# f2838x_cm_ethernetss_regs register map
Vendor: Texas Instruments
Peripheral module from a debugger description file (folder C2000).
Address unit: 16 bits
Registers are 32-bit, read-write, no defined reset value unless marked. A register's access mark holds for its fields unless they carry their own. Offsets are as the file gives them; lines under a group give offsets from that group; [hi:lo] are bit positions; {n}, {i} and the like mark numbered series; 'fields as' and 'values as' point back to an identical list; <NAME> marks a mode.

## ETHERNETSS_REGS — ETHERNETSS Registers
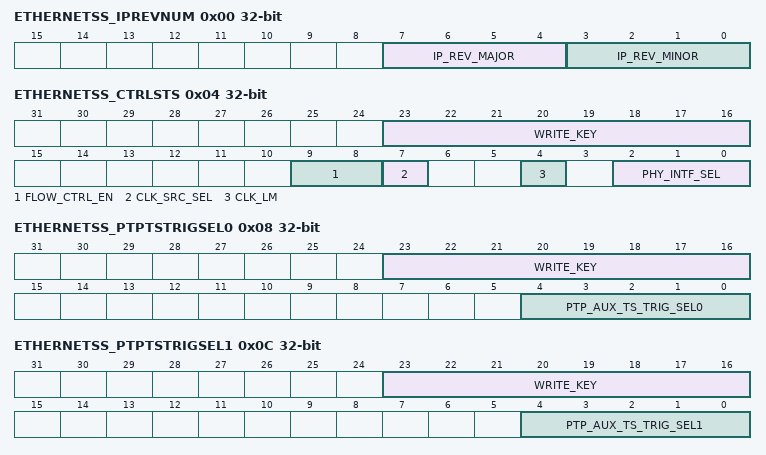
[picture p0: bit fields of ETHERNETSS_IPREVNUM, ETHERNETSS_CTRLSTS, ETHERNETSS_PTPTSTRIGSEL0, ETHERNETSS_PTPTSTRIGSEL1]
0x00 ETHERNETSS_IPREVNUM ro — IP Revision Number
  [7:4] IP_REV_MAJOR — Major IP Revision Number
  [3:0] IP_REV_MINOR — Minor IP Revision Number
0x04 ETHERNETSS_CTRLSTS access per field — Control Register
  [23:16] WRITE_KEY rw — Key to enable writing lock
  [9:8] FLOW_CTRL_EN rw — Back-pressure enable per receive queue.
  [7] CLK_SRC_SEL rw — Internal Clock Selection
  [4] CLK_LM ro — MII Loop-back mode clock select
  [2:0] PHY_INTF_SEL rw — PHY Type Selection
0x08 ETHERNETSS_PTPTSTRIGSEL0 — PTP Trigger-0 select
  [23:16] WRITE_KEY — Key to enable writing lock
  [4:0] PTP_AUX_TS_TRIG_SEL0 — Trigger select for Auxillary TS capture - 0
0x0C ETHERNETSS_PTPTSTRIGSEL1 — PTP Trigger-1 select
  [23:16] WRITE_KEY — Key to enable writing lock
  [4:0] PTP_AUX_TS_TRIG_SEL1 — Trigger select for Auxillary TS capture - 1
0x10 ETHERNETSS_PTPTSSWTRIG0 — PTP SW Trigger-0
  [0] PTP_AUX_TS_SW_TRIG0 — SW trigger for AUX TS capture for trigger-0
0x14 ETHERNETSS_PTPTSSWTRIG1 — PTP SW Trigger-1
  [0] PTP_AUX_TS_SW_TRIG1 — SW trigger for AUX TS capture for trigger-1
0x18 ETHERNETSS_PTPPPSR0 ro — PTP PPS-0 Read
  [0] PTP_PPS_R0 — Registered value of Pulse Per Second-0
0x1C ETHERNETSS_PTPPPSR1 ro — PTP PPS-1 Read
  [0] PTP_PPS_R1 — Registered value of Pulse Per Second-1
0x20 ETHERNETSS_PTP_TSRL ro — PTP timestamp read lower 32 bits
  [31:0] TSR_L — Time-stamp o/p from the EQOS Low
0x24 ETHERNETSS_PTP_TSRH ro — PTP timestamp read upper 32 bits
  [31:0] TSR_H — Time-stamp o/p from the EQOS High
0x28 ETHERNETSS_PTP_TSWL — External Timestamp write lower 32 bits
  [31:0] TSW_L — Time-stamp i/p from external to EQOS
0x2C ETHERNETSS_PTP_TSWH — External Timestamp write upper 32 bits
  [31:0] TSW_H — Time-stamp i/p from external to EQOS
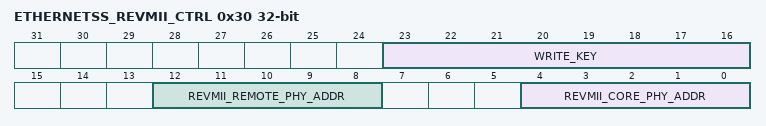
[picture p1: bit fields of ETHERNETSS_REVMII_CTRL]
0x30 ETHERNETSS_REVMII_CTRL — RevMII Phy Address controls
  [23:16] WRITE_KEY — Key to enable writing lock
  [12:8] REVMII_REMOTE_PHY_ADDR — RevMII Remote Register Space offset
  [4:0] REVMII_CORE_PHY_ADDR — RevMII Core Register Space offset
